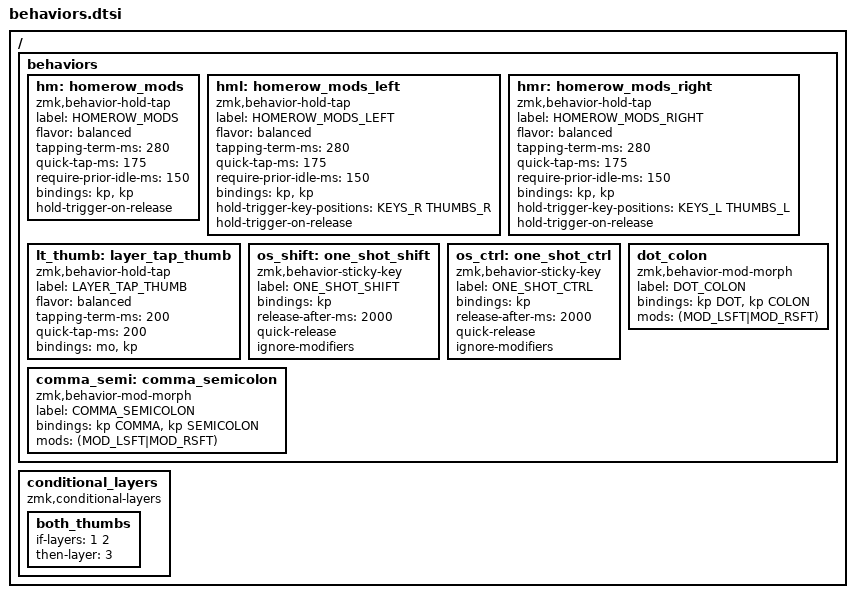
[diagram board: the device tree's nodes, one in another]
/*
 * Symmetric Home Row Mods for Glove80
 * Optimized for small hands and RSI prevention
 * 
 * Left hand: GUI, Alt, Shift, Ctrl (pinky to index)
 * Right hand: Ctrl, Shift, Alt, GUI (index to pinky)
 */

// Key position groups for Glove80
#define KEYS_L 0 1 2 3 4 10 11 12 13 14 20 21 22 23 24 30 31 32 33 34 40 41 42 43 44
#define KEYS_R 5 6 7 8 9 15 16 17 18 19 25 26 27 28 29 35 36 37 38 39 45 46 47 48 49
#define THUMBS_L 50 51 52 53 54 55
#define THUMBS_R 56 57 58 59 60 61

/ {
    behaviors {
        // Symmetric home row mods - same timing for both hands
        hm: homerow_mods {
            compatible = "zmk,behavior-hold-tap";
            label = "HOMEROW_MODS";
            #binding-cells = <2>;
            flavor = "balanced";
            tapping-term-ms = <280>;
            quick-tap-ms = <175>;
            require-prior-idle-ms = <150>;
            bindings = <&kp>, <&kp>;
            hold-trigger-on-release;
        };
        
        // Home row mods for left hand (with right hand activation)
        hml: homerow_mods_left {
            compatible = "zmk,behavior-hold-tap";
            label = "HOMEROW_MODS_LEFT";
            #binding-cells = <2>;
            flavor = "balanced";
            tapping-term-ms = <280>;
            quick-tap-ms = <175>;
            require-prior-idle-ms = <150>;
            bindings = <&kp>, <&kp>;
            hold-trigger-key-positions = <KEYS_R THUMBS_R>;
            hold-trigger-on-release;
        };
        
        // Home row mods for right hand (with left hand activation)
        hmr: homerow_mods_right {
            compatible = "zmk,behavior-hold-tap";
            label = "HOMEROW_MODS_RIGHT";
            #binding-cells = <2>;
            flavor = "balanced";
            tapping-term-ms = <280>;
            quick-tap-ms = <175>;
            require-prior-idle-ms = <150>;
            bindings = <&kp>, <&kp>;
            hold-trigger-key-positions = <KEYS_L THUMBS_L>;
            hold-trigger-on-release;
        };
        
        // Layer tap for thumb keys
        lt_thumb: layer_tap_thumb {
            compatible = "zmk,behavior-hold-tap";
            label = "LAYER_TAP_THUMB";
            #binding-cells = <2>;
            flavor = "balanced";
            tapping-term-ms = <200>;
            quick-tap-ms = <200>;
            bindings = <&mo>, <&kp>;
        };
        
        // One-shot modifiers for reduced holding
        os_shift: one_shot_shift {
            compatible = "zmk,behavior-sticky-key";
            label = "ONE_SHOT_SHIFT";
            #binding-cells = <1>;
            bindings = <&kp>;
            release-after-ms = <2000>;
            quick-release;
            ignore-modifiers;
        };
        
        os_ctrl: one_shot_ctrl {
            compatible = "zmk,behavior-sticky-key";
            label = "ONE_SHOT_CTRL";
            #binding-cells = <1>;
            bindings = <&kp>;
            release-after-ms = <2000>;
            quick-release;
            ignore-modifiers;
        };
        
        // Mod-morph for shift functions
        comma_semi: comma_semicolon {
            compatible = "zmk,behavior-mod-morph";
            label = "COMMA_SEMICOLON";
            #binding-cells = <0>;
            bindings = <&kp COMMA>, <&kp SEMICOLON>;
            mods = <(MOD_LSFT|MOD_RSFT)>;
        };
        
        dot_colon: dot_colon {
            compatible = "zmk,behavior-mod-morph";
            label = "DOT_COLON";
            #binding-cells = <0>;
            bindings = <&kp DOT>, <&kp COLON>;
            mods = <(MOD_LSFT|MOD_RSFT)>;
        };
    };
    
    // Conditional layers for better modifier handling
    conditional_layers {
        compatible = "zmk,conditional-layers";
        
        // Example: Both thumbs pressed = special layer
        both_thumbs {
            if-layers = <1 2>;
            then-layer = <3>;
        };
    };
};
